AUTOSAR XML (schema 4-3-0)
package /Example
  client server interface MyInterface1
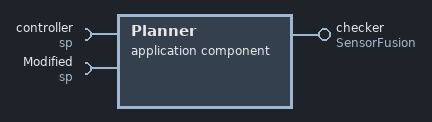
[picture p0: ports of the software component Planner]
  application sw component type Planner
    provide port checker: provided-interface=SensorFusion
    require port controller: required-interface=sp
    require port Modified: required-interface=sp
package /p1
  sender receiver interface SensorFusion
  client server interface ActuatorControl
package /p1/p2/p3
  sender receiver interface Sr
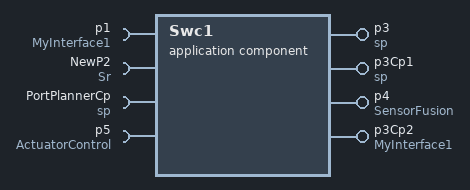
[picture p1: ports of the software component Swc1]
  application sw component type Swc1
    require port p1: required-interface=MyInterface1
    require port NewP2: required-interface=Sr
    require port PortPlannerCp: required-interface=sp
    provide port p3: provided-interface=sp
    provide port p3Cp1: provided-interface=sp
    provide port p4: provided-interface=SensorFusion
    require port p5: required-interface=ActuatorControl
    provide port p3Cp2: provided-interface=MyInterface1
  client server interface sp
